# NAND register map
Registers from a debugger description file.
Registers are 32-bit, access not given, no defined reset value unless marked. A register's access mark holds for its fields unless they carry their own. Addresses are absolute; registers are grouped by the start of their names; lines under a group give offsets from that group; [hi:lo] are bit positions; {n}, {i} and the like mark numbered series; 'fields as' and 'values as' point back to an identical list; <NAME> marks a mode.

## NAND
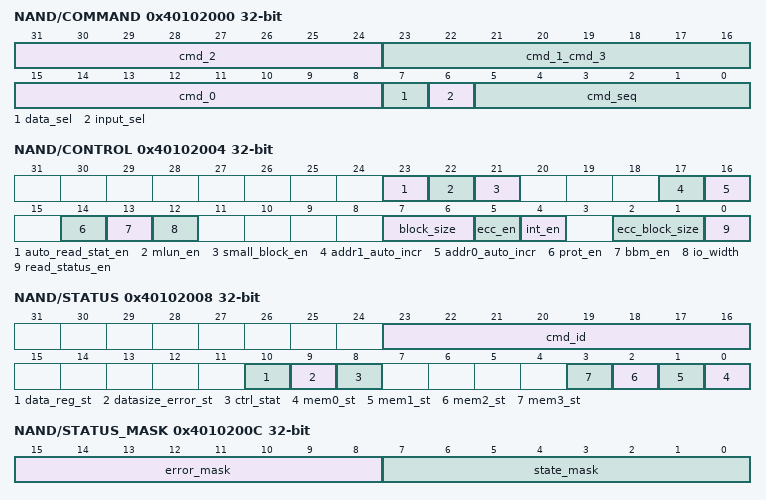
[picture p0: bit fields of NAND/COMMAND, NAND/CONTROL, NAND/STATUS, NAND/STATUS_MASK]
0x40102000 NAND/COMMAND
  [31:24] cmd_2, [23:16] cmd_1_cmd_3, [15:8] cmd_0, [7] data_sel, [6] input_sel, [5:0] cmd_seq
0x40102004 NAND/CONTROL
  [23] auto_read_stat_en, [22] mlun_en, [21] small_block_en, [17] addr1_auto_incr, [16] addr0_auto_incr, [14] prot_en, [13] bbm_en, [12] io_width, [7:6] block_size, [5] ecc_en, [4] int_en, [2:1] ecc_block_size, [0] read_status_en
0x40102008 NAND/STATUS ro
  [23:16] cmd_id, [10] data_reg_st, [9] datasize_error_st, [8] ctrl_stat, [n] mem{n}_st (n=0..3)
0x4010200C NAND/STATUS_MASK
  [15:8] error_mask, [7:0] state_mask
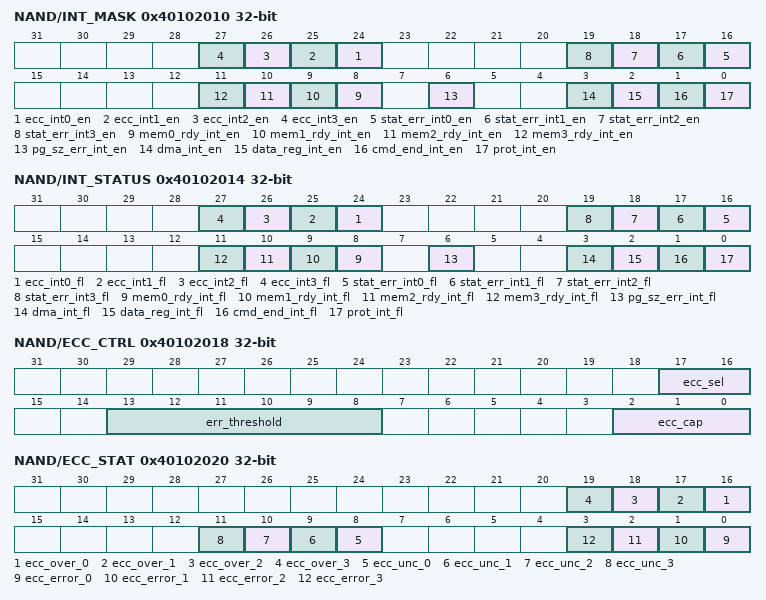
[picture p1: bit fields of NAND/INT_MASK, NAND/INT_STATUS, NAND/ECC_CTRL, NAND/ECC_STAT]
0x40102010 NAND/INT_MASK
  [n+24] ecc_int{n}_en (n=0..3), [n+16] stat_err_int{n}_en (n=0..3), [n+8] mem{n}_rdy_int_en (n=0..3), [6] pg_sz_err_int_en, [3] dma_int_en, [2] data_reg_int_en, [1] cmd_end_int_en, [0] prot_int_en
0x40102014 NAND/INT_STATUS
  [n+24] ecc_int{n}_fl (n=0..3), [n+16] stat_err_int{n}_fl (n=0..3), [n+8] mem{n}_rdy_int_fl (n=0..3), [6] pg_sz_err_int_fl, [3] dma_int_fl, [2] data_reg_int_fl, [1] cmd_end_int_fl, [0] prot_int_fl
0x40102018 NAND/ECC_CTRL
  [17:16] ecc_sel, [13:8] err_threshold, [2:0] ecc_cap
0x4010201C NAND/ECC_OFFSET
  [15:0] ecc_offset
0x40102020 NAND/ECC_STAT
  [n+16] ecc_over_{n} (n=0..3), [n+8] ecc_unc_{n} (n=0..3), [n] ecc_error_{n} (n=0..3)
0x40102024 NAND/ADDR0_COL
  [15:0] addr0_col
0x40102028 NAND/ADDR0_ROW
  [23:0] addr0_row
0x4010202C NAND/ADDR1_COL
  [15:0] addr1_col
0x40102030 NAND/ADDR1_ROW
  [23:0] addr1_row
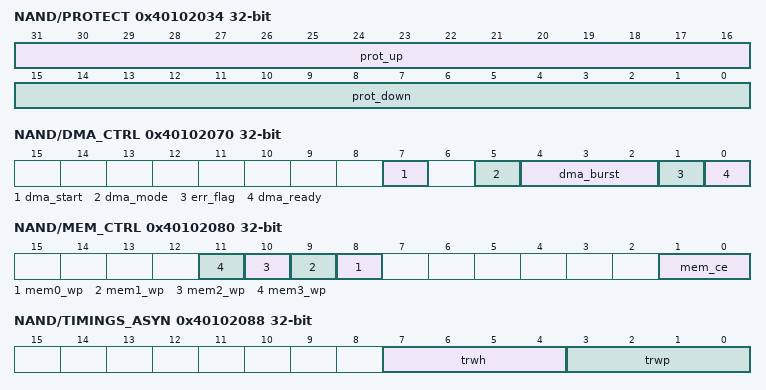
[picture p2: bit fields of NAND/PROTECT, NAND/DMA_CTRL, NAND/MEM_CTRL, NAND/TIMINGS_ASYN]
0x40102034 NAND/PROTECT
  [31:16] prot_up, [15:0] prot_down
0x40102038 NAND/FIFO_DATA
  [31:0] fifo_data
0x4010203C NAND/DATA_REG ro
  [31:0] data_reg
0x40102040 NAND/DATA_REG_SIZE
  [1:0] data_reg_size
{0x40102044+4i} NAND/DEV{i}_PTR (i=0..3)
  [31:0] ptr_addr
0x40102064 NAND/DMA_ADDR
  [31:0] dma_addr_l
0x4010206C NAND/DMA_CNT
  [31:0] cnt_init
0x40102070 NAND/DMA_CTRL
  [7] dma_start, [5] dma_mode, [4:2] dma_burst, [1] err_flag ro, [0] dma_ready ro
0x40102074 NAND/BBM_CTRL
  [0] rmp_init
0x40102080 NAND/MEM_CTRL
  [n+8] mem{n}_wp (n=0..3), [1:0] mem_ce
0x40102084 NAND/DATA_SIZE
  [14:0] data_size
0x40102088 NAND/TIMINGS_ASYN
  [7:4] trwh, [3:0] trwp
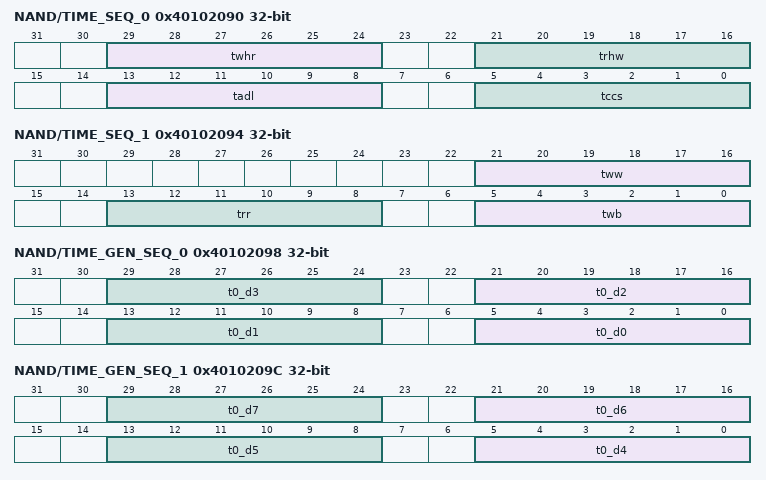
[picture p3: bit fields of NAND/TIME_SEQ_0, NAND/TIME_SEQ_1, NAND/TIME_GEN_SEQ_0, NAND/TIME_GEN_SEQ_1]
0x40102090 NAND/TIME_SEQ_0
  [29:24] twhr, [21:16] trhw, [13:8] tadl, [5:0] tccs
0x40102094 NAND/TIME_SEQ_1
  [21:16] tww, [13:8] trr, [5:0] twb
0x40102098 NAND/TIME_GEN_SEQ_0
  [8n+5:8n] t0_d{n} (n=0..3)
0x4010209C NAND/TIME_GEN_SEQ_1
  [8n-27:8n-32] t0_d{n} (n=4..7)
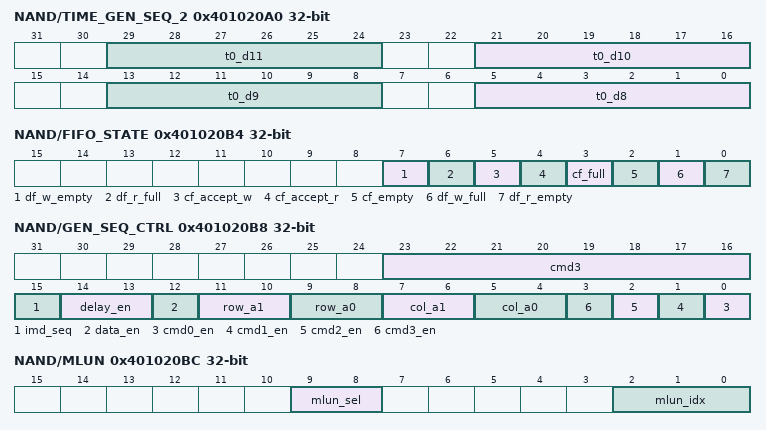
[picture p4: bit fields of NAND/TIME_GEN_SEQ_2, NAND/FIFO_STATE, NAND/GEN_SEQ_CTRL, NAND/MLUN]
0x401020A0 NAND/TIME_GEN_SEQ_2
  [8n-59:8n-64] t0_d{n} (n=8..11)
0x401020B0 NAND/FIFO_INIT wo
  [0] fifo_init
0x401020B4 NAND/FIFO_STATE ro
  [7] df_w_empty, [6] df_r_full, [5] cf_accept_w, [4] cf_accept_r, [3] cf_full, [2] cf_empty, [1] df_w_full, [0] df_r_empty
0x401020B8 NAND/GEN_SEQ_CTRL
  [23:16] cmd3, [15] imd_seq, [14:13] delay_en, [12] data_en, [11:10] row_a1, [9:8] row_a0, [7:6] col_a1, [5:4] col_a0, [n] cmd{n}_en (n=0..3)
0x401020BC NAND/MLUN
  [9:8] mlun_sel, [2:0] mlun_idx
{0x401020C0+4i} NAND/DEV{i}_SIZE (i=0..3)
  [11:0] dev_size
0x40102114 NAND/DMA_TLVL
  [7:0] dma_tlvl
0x40102124 NAND/CMD_MARK wo
  [7:0] cmd_id
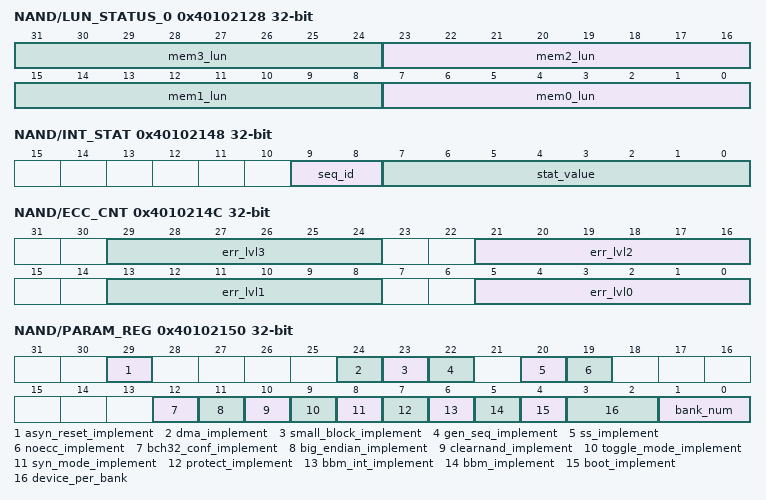
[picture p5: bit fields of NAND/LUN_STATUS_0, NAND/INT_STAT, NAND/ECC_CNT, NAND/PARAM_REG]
0x40102128 NAND/LUN_STATUS_0 ro
  [8n+7:8n] mem{n}_lun (n=0..3)
0x40102134 NAND/TIME_GEN_SEQ_3
  [5:0] t0_d12
0x40102148 NAND/INT_STAT
  [9:8] seq_id, [7:0] stat_value
0x4010214C NAND/ECC_CNT
  [8n+5:8n] err_lvl{n} (n=0..3)
0x40102150 NAND/PARAM_REG ro
  [29] asyn_reset_implement, [24] dma_implement, [23] small_block_implement, [22] gen_seq_implement, [20] ss_implement, [19] noecc_implement, [12] bch32_conf_implement, [11] big_endian_implement, [10] clearnand_implement, [9] toggle_mode_implement, [8] syn_mode_implement, [7] protect_implement, [6] bbm_int_implement, [5] bbm_implement, [4] boot_implement, [3:2] device_per_bank, [1:0] bank_num
